# CS32F031x register map
File version: 1.0
Registers are 32-bit, read-write, reset 0x0 unless marked. A register's access mark holds for its fields unless they carry their own. Offsets are from the block's base; lines under a group give offsets from that group; [hi:lo] are bit positions; {n}, {i} and the like mark numbered series; 'fields as' and 'values as' point back to an identical list; <NAME> marks a mode.

## Memory map
0x40000000 TIM2 size 0x400 — General-purpose-timers
0x40000400 TIM3 size 0x400
0x40001000 TIM6 size 0x400 — General-purpose-timers
0x40002000 TIM14 size 0x400 — General-purpose-timers
0x40002800 RTC size 0x400 — Real-time clock
0x40002C00 WWDT size 0x400 — Window Watchdog Timer
0x40003000 FWDT size 0x400 — Free Watchdog Timer
0x40003800 SPI2 size 0x400
0x40004400 USART2 size 0x400
0x40004800 USART3 size 0x400
0x40004C00 USART4 size 0x400
0x40005000 USART5 size 0x400
0x40005400 I2C1 size 0x400 — Inter-integrated circuit
0x40005800 I2C2 size 0x400
0x40007000 PMU size 0x400 — Power management unit
0x40010000 SYSCFG size 0x400 — System configuration
0x40010400 EXTI size 0x400 — External interrupt/event controller
0x40011400 USART6 size 0x400
0x40011800 USART7 size 0x400
0x40011C00 USART8 size 0x400
0x40012400 ADC size 0x400 — Analog-to-digital converter
0x40012C00 TIM1 size 0x400 — Advanced-timers
0x40013000 SPI1 size 0x400 — Serial peripheral interface
0x40013800 USART1 size 0x400 — Universal synchronous asynchronous receiver transmitter
0x40014000 TIM15 size 0x400 — General-purpose-timers
0x40014400 TIM16 size 0x400
0x40014800 TIM17 size 0x400
0x40015800 DBG size 0x400 — Debug support
0x40020000 DMA size 0x400 — DMA controller
0x40021000 RCU size 0x400 — Reset and clock unit
0x40022000 FMC size 0x400 — FLASH Memory Control
0x40023000 CRC size 0x400 — cyclic redundancy check calculation unit
0x48000000 GPIOA size 0x400 — General-purpose I/Os
0x48000400 GPIOB size 0x400
0x48000800 GPIOC size 0x400
0x48000C00 GPIOD size 0x400
0x48001000 GPIOE size 0x400
0x48001400 GPIOF size 0x400 — General-purpose I/Os
0xE000E100 NVIC size 0x33D — Nested Vectored Interrupt Controller

## Interrupts
0 WWDT — Window Watchdog Timer interrupt
1 LVD (EXTI) — LVD through EXTI line detection
2 RTC — RTC global interrupt
3 FLASH (FMC) — Flash global interrupt
4 RCU — RCU global interrupt
5 EXTI0_1 (EXTI) — EXTI Line[1:0] interrupts
6 EXTI2_3 (EXTI) — EXTI Line[3:2] interrupts
7 EXTI4_15 (EXTI) — EXTI Line15 and EXTI4 interrupts
9 DMA1_Channel1 (DMA) — DMA channel 1 interrupt
10 DMA1_Channel2_3 (DMA) — DMA channel 2 and 3 interrupts
11 DMA1_Channel4_5 (DMA) — DMA channel 4 and 5 interrupts
12 ADC_COMP (ADC) — ADC and comparator 1 and 2
13 TIM1_BRK_UP_TRG_COM (TIM1) — TIM1 Break, Update, Trigger and Commutation
14 TIM1_CC (TIM1) — TIM1 Capture Compare interrupt
15 TIM2 — TIM2 global interrupt
16 TIM3 — TIM3 global interrupt
17 TIM6 — TIM6 global interrupt
19 TIM14 — TIM14 global interrupt
20 TIM15 — TIM15 global interrupt
21 TIM16 — TIM16 global interrupt
22 TIM17 — TIM17 global interrupt
23 I2C1 — I2C1 global interrupt
24 I2C2 — I2C2 global interrupt
25 SPI1 — SPI1_global_interrupt
26 SPI2 — SPI2 global interrupt
27 USART1 — USART1 global interrupt
28 USART2 — USART2 global interrupt
29 USART3_8 (USART{n} (n=3..8)) — USART3_8 global interrupt

## CRC — cyclic redundancy check calculation unit
Base 0x40023000
0x00 DATA reset 0xFFFFFFFF
  [31:0] DATA — Data register bits
0x04 FREDATA — free data register
  [7:0] FREDATA — Free Data register bits
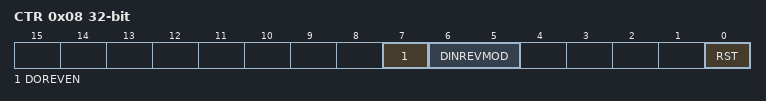
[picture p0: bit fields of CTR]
0x08 CTR — Control register
  [7] DOREVEN — Output data Reverse enable
  [6:5] DINREVMOD — Input data Reverse mode selection
  [0] RST — reset bit
0x0C INITCFG reset 0xFFFFFFFF — CRC initial value configuration register
  [31:0] INITCFG — CRC initial value configuration bits

## GPIOF — General-purpose I/Os
Base 0x48001400
Same registers: GPIOB 0x48000400, GPIOC 0x48000800, GPIOD 0x48000C00, GPIOE 0x48001000
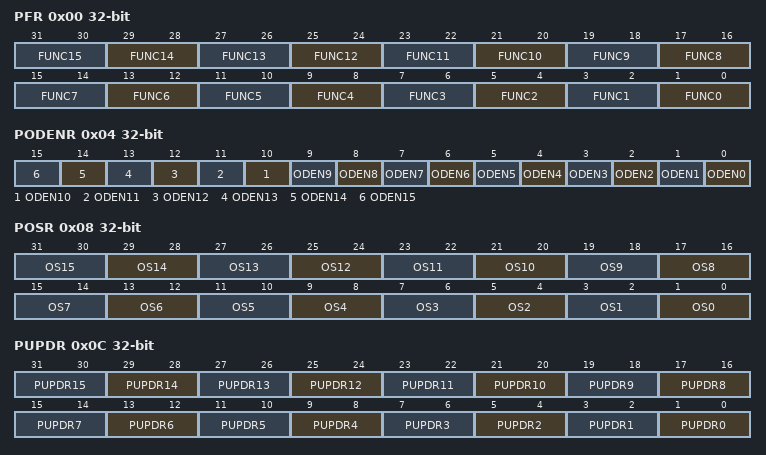
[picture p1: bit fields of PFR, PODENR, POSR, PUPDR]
0x00 PFR — GPIO port function register
  [2n+1:2n] FUNC{n} (n=0..15) — Port i function (j = 0..15)
0x04 PODENR — GPIO port output open-drain enable register
  [n] ODEN{n} (n=0..15) — Port i output open-drain enable {n}
0x08 POSR — GPIO port output speed register
  [2n+1:2n] OS{n} (n=0..15) — Port i output speed (i= 0..15)
0x0C PUPDR — GPIO port pull-up/pull-down register
  [2n+1:2n] PUPDR{n} (n=0..15) — Port i configuration bits (i = 0..15)
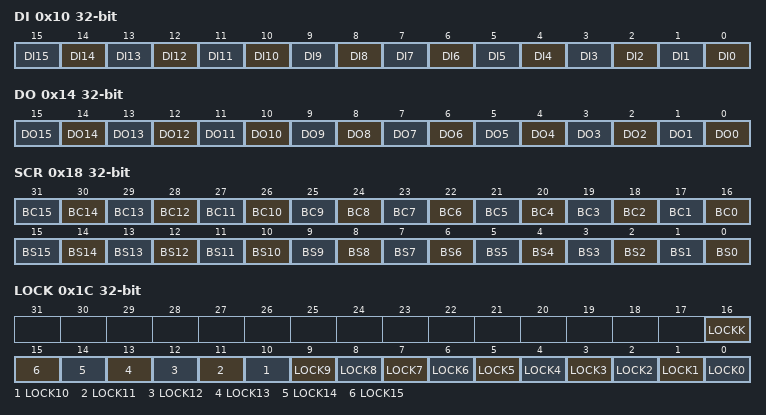
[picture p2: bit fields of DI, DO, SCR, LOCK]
0x10 DI ro — GPIO port data input register
  [n] DI{n} (n=0..15) — Port i data input j (j = 0..15)
0x14 DO — GPIO port data output register
  [n] DO{n} (n=0..15) — Port i data output j (j = 0..15)
0x18 SCR wo — GPIO port set/clear register
  [n+16] BC{n} (n=0..15) — Port i bit clear j (i = 0..15)
  [n] BS{n} (n=0..15) — Port i bit set j (i = 0..15)
0x1C LOCK — GPIO port lock register
  [16] LOCKK — Lock sequence key
  [n] LOCK{n} (n=0..15) — Port i lock j (i = 0..15)
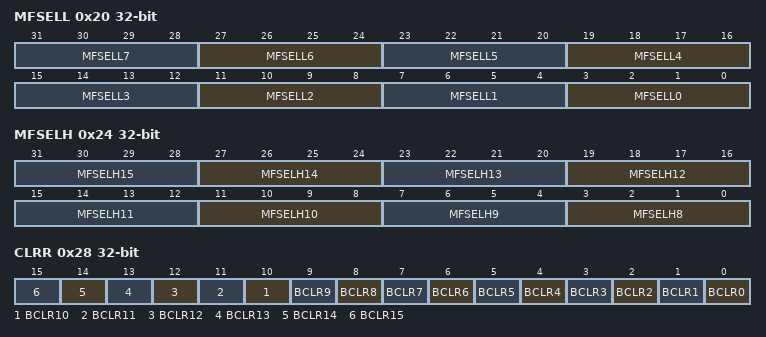
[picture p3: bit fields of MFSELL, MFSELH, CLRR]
0x20 MFSELL — GPIO multi-function selection low register
  [4n+3:4n] MFSELL{n} (n=0..7) — Port i multi-function selection j (i = 0..7)
0x24 MFSELH — GPIO multi-function selection high register
  [4n-29:4n-32] MFSELH{n} (n=8..15) — Port i multi-function selection j (i = 8..15)
0x28 CLRR wo — GPIO port clear register
  [n] BCLR{n} (n=0..15) — Port i bit clear j

## GPIOA — General-purpose I/Os
Base 0x48000000
Registers as GPIOF; these are added or differ:
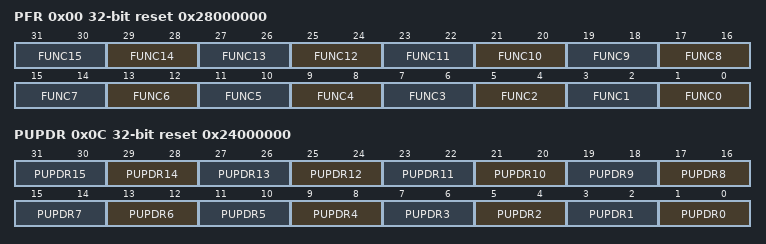
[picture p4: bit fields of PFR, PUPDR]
0x00 PFR reset 0x28000000 — GPIO port function register
  [2n+1:2n] FUNC{n} (n=0..15) — Port i function (j = 0..15)
0x0C PUPDR reset 0x24000000 — GPIO port pull-up/pull-down register
  [2n+1:2n] PUPDR{n} (n=0..15) — Port i configuration bits (i = 0..15)
